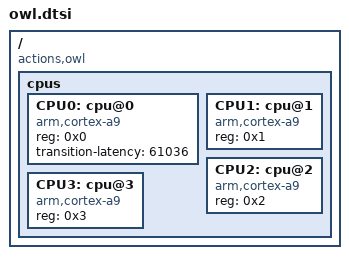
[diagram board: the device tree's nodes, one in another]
/include/ "skeleton.dtsi"

/ {
	compatible = "actions,owl";

	cpus {
		#size-cells = <0>;
		#address-cells = <1>;

		CPU0: cpu@0 {
			device_type = "cpu";
			compatible = "arm,cortex-a9";
			reg = <0x0>;

			transition-latency = <61036>; /* two CLK32 periods */
		};

		CPU1: cpu@1 {
			device_type = "cpu";
			compatible = "arm,cortex-a9";
			reg = <0x1>;
		};
		
		CPU2: cpu@2 {
			device_type = "cpu";
			compatible = "arm,cortex-a9";
			reg = <0x2>;
		};
		
		CPU3: cpu@3 {
			device_type = "cpu";
			compatible = "arm,cortex-a9";
			reg = <0x3>;
		};
	};
	
	/* owl dtsi location is owl/gs705a/config/dts/xxx.dtsi */
};
